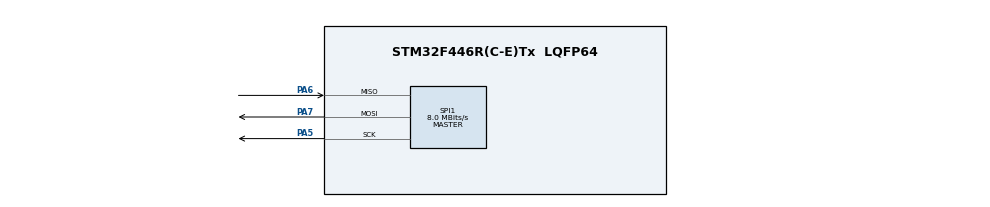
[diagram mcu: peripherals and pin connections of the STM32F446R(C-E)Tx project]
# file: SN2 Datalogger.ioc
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Mcu.Family=STM32F4
Mcu.Name=STM32F446R(C-E)Tx
Mcu.Package=LQFP64
NVIC.PriorityGroup=NVIC_PRIORITYGROUP_4
NVIC.SPI1_IRQn=true\:0\:0\:false\:false\:true\:true\:true\:true
PA5.Mode=Full_Duplex_Master
PA5.Signal=SPI1_SCK
PA6.Mode=Full_Duplex_Master
PA6.Signal=SPI1_MISO
PA7.Mode=Full_Duplex_Master
PA7.Signal=SPI1_MOSI
ProjectManager.HeapSize=0x200
ProjectManager.StackSize=0x400
ProjectManager.TargetToolchain=STM32CubeIDE
RCC.CortexFreq_Value=16000000
RCC.USBFreq_Value=96000000
RCC.VCOOutputFreq_Value=192000000
SPI1.CalculateBaudRate=8.0 MBits/s
SPI1.Direction=SPI_DIRECTION_2LINES
SPI1.Mode=SPI_MODE_MASTER
SPI1.VirtualType=VM_MASTER
VP_FATFS_VS_Generic.Mode=User_defined
board=custom

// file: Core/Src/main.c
/* USER CODE BEGIN Header */
/**
  ******************************************************************************
  * @file           : main.c
  * @brief          : Main program body
  ******************************************************************************
  * @attention
  *
  * Copyright (c) 2022 STMicroelectronics.
  * All rights reserved.
  *
  * This software is licensed under terms that can be found in the LICENSE file
  * in the root directory of this software component.
  * If no LICENSE file comes with this software, it is provided AS-IS.
  *
  ******************************************************************************
  */
/* USER CODE END Header */
#include "main.h"
#include "fatfs.h"
#include <stdio.h>
#include <string.h>
#include <stdarg.h>

SPI_HandleTypeDef hspi;

/* USER CODE BEGIN PV */
//Change Pins
//#define DDR_SPI
//#define PORT_SPI
#define SD_CS           PB1
#define MOSI            PINA6
#define MISO            PINA7
#define SCK             PINA8
/* USER CODE END PV */

void SystemClock_Config(void);
static void MX_GPIO_Init(void);
static void MX_SPI1_Init(void);

int main(void)
{

  /* MCU Configuration--------------------------------------------------------*/

  /* Reset of all peripherals, Initializes the Flash interface and the Systick. */
  HAL_Init();

  /* Configure the system clock */
  SystemClock_Config();

  /* Initialize all configured peripherals */
  MX_GPIO_Init();
  MX_SPI1_Init();
  MX_FATFS_Init();

  /* Infinite loop */
  /* USER CODE BEGIN WHILE */
  while (1)
  {
	  HAL_Delay(1000); //a short delay is important to let the SD card settle
  }

  //some variables for FatFs
  FATFS FatFs; 	//Fatfs handle
  FIL fil; 		//File handle
  FRESULT fres; //Result after operations

  //Open the file system
  fres = f_mount(&FatFs, "", 1); //1=mount now
  if (fres != FR_OK) {
	while(1);
  }

  //Information about memory from the SD card
  DWORD free_clusters, free_sectors, total_sectors;

  FATFS* getFreeFs;

  fres = f_getfree("", &free_clusters, &getFreeFs);
  if (fres != FR_OK) {
	while(1);
  }

  //Formula comes from documentation
  total_sectors = (getFreeFs->n_fatent - 2) * getFreeFs->csize;
  free_sectors = free_clusters * getFreeFs->csize;

  //Now let's try to open file "test.txt". Replace this
  //with the file convention we will use for the actual system
  //For example, organizing by different sensor files
  fres = f_open(&fil, "test.txt", FA_READ);
  if (fres != FR_OK) {
	while(1);
  }

  //Read sensor data onto the text file
  BYTE readBuf[30];

  //We can either use f_read OR f_gets to get data out of files
  //f_gets is a wrapper on f_read that does some string formatting for us
  TCHAR* rres = f_gets((TCHAR*)readBuf, 30, &fil);
  if(rres != 0) {
	null;
  } else {
	null;
  }

  f_close(&fil);

  //write a file "write.txt". Will be writing to files based on the sensor
  // and type of data.
  fres = f_open(&fil, "write.txt", FA_WRITE | FA_OPEN_ALWAYS | FA_CREATE_ALWAYS);
  if(fres == FR_OK) {
	null;
  } else {
	null;
  }

  //Copy in a string into the file
  strncpy((char*)readBuf, "a new file is made!", 19);
  UINT bytesWrote;
  fres = f_write(&fil, readBuf, 19, &bytesWrote);
  if(fres == FR_OK) {
	null;
  } else {
	null;
  }
  f_close(&fil);

  //de-mount the drive
  f_mount(NULL, "", 0);

  /* USER CODE END 2 */

  /* Infinite loop */
  /* USER CODE BEGIN WHILE */
  while (1)
  {
    /* USER CODE END WHILE */

  }
}

void SystemClock_Config(void)
{
  RCC_OscInitTypeDef RCC_OscInitStruct = {0};
  RCC_ClkInitTypeDef RCC_ClkInitStruct = {0};

  /** Configure the main internal regulator output voltage
  */
  __HAL_RCC_PWR_CLK_ENABLE();
  __HAL_PWR_VOLTAGESCALING_CONFIG(PWR_REGULATOR_VOLTAGE_SCALE3);

  /** Initializes the RCC Oscillators according to the specified parameters
  * in the RCC_OscInitTypeDef structure.
  */
  RCC_OscInitStruct.OscillatorType = RCC_OSCILLATORTYPE_HSI;
  RCC_OscInitStruct.HSIState = RCC_HSI_ON;
  RCC_OscInitStruct.HSICalibrationValue = RCC_HSICALIBRATION_DEFAULT;
  RCC_OscInitStruct.PLL.PLLState = RCC_PLL_NONE;
  if (HAL_RCC_OscConfig(&RCC_OscInitStruct) != HAL_OK)
  {
    Error_Handler();
  }

  /** Initializes the CPU, AHB and APB buses clocks
  */
  RCC_ClkInitStruct.ClockType = RCC_CLOCKTYPE_HCLK|RCC_CLOCKTYPE_SYSCLK
                              |RCC_CLOCKTYPE_PCLK1|RCC_CLOCKTYPE_PCLK2;
  RCC_ClkInitStruct.SYSCLKSource = RCC_SYSCLKSOURCE_HSI;
  RCC_ClkInitStruct.AHBCLKDivider = RCC_SYSCLK_DIV1;
  RCC_ClkInitStruct.APB1CLKDivider = RCC_HCLK_DIV1;
  RCC_ClkInitStruct.APB2CLKDivider = RCC_HCLK_DIV1;

  if (HAL_RCC_ClockConfig(&RCC_ClkInitStruct, FLASH_LATENCY_0) != HAL_OK)
  {
    Error_Handler();
  }
}

static void MX_SPI1_Init(void)
{

  /* SPI1 parameter configuration*/
  hspi.Instance = SPI1;
  hspi.Init.Mode = SPI_MODE_MASTER;
  hspi.Init.Direction = SPI_DIRECTION_2LINES;
  hspi.Init.DataSize = SPI_DATASIZE_8BIT;
  hspi.Init.CLKPolarity = SPI_POLARITY_LOW;
  hspi.Init.CLKPhase = SPI_PHASE_1EDGE;
  hspi.Init.NSS = SPI_NSS_SOFT;
  hspi.Init.BaudRatePrescaler = SPI_BAUDRATEPRESCALER_2;
  hspi.Init.FirstBit = SPI_FIRSTBIT_MSB;
  hspi.Init.TIMode = SPI_TIMODE_DISABLE;
  hspi.Init.CRCCalculation = SPI_CRCCALCULATION_DISABLE;
  hspi.Init.CRCPolynomial = 10;
  if (HAL_SPI_Init(&hspi) != HAL_OK)
  {
    Error_Handler();
  }

}

static void MX_GPIO_Init(void)
{

  /* GPIO Ports Clock Enable */
  __HAL_RCC_GPIOA_CLK_ENABLE();

}

/* USER CODE BEGIN 4 */
static void isPresent() {

}

static void read() {

}

static void write(, uint8 data, ) {

}
/* USER CODE END 4 */

void Error_Handler(void)
{
  __disable_irq();
  while (1)
  {
  }
}
